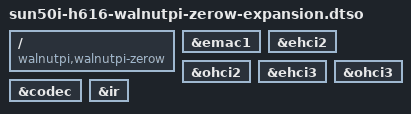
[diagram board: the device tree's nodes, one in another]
/dts-v1/;
/plugin/;

/*
 * Walnut Pi ZeroW FPC expansion board: 10/100M Ethernet (RJ45 with
 * link/speed LEDs from the EPHY), 2x USB 2.0 host (USB2/USB3
 * controllers), 3.5mm line-out, IR receiver.
 * Enable with: overlays=walnutpi-zerow-expansion
 */

/ {
	compatible = "walnutpi,walnutpi-zerow", "allwinner,sun50i-h618";

	fragment@0 {
		target = <&emac1>;
		__overlay__ {
			status = "okay";
		};
	};

	fragment@1 {
		target = <&ehci2>;
		__overlay__ {
			status = "okay";
		};
	};

	fragment@2 {
		target = <&ohci2>;
		__overlay__ {
			status = "okay";
		};
	};

	fragment@3 {
		target = <&ehci3>;
		__overlay__ {
			status = "okay";
		};
	};

	fragment@4 {
		target = <&ohci3>;
		__overlay__ {
			status = "okay";
		};
	};

	fragment@5 {
		target = <&codec>;
		__overlay__ {
			status = "okay";
		};
	};

	fragment@6 {
		target = <&ir>;
		__overlay__ {
			status = "okay";
		};
	};
};
